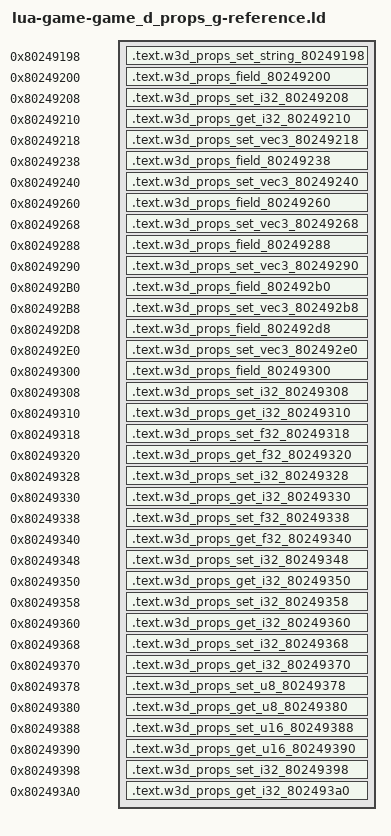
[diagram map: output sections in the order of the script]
/* Generated reference-only placements. All bodies are source-built. */
OUTPUT_FORMAT("elf32-powerpc")
OUTPUT_ARCH(powerpc)
ENTRY(w3d_props_set_string_80249198)
_SDA_BASE_ = 0x804b2540;
_SDA2_BASE_ = 0x804c2540;
w3d_string_release_header = 0x8020bb2c;
SECTIONS {
  .text.w3d_props_set_string_80249198 0x80249198 : { *(.text.w3d_props_set_string_80249198) }
  .text.w3d_props_field_80249200 0x80249200 : { *(.text.w3d_props_field_80249200) }
  .text.w3d_props_set_i32_80249208 0x80249208 : { *(.text.w3d_props_set_i32_80249208) }
  .text.w3d_props_get_i32_80249210 0x80249210 : { *(.text.w3d_props_get_i32_80249210) }
  .text.w3d_props_set_vec3_80249218 0x80249218 : { *(.text.w3d_props_set_vec3_80249218) }
  .text.w3d_props_field_80249238 0x80249238 : { *(.text.w3d_props_field_80249238) }
  .text.w3d_props_set_vec3_80249240 0x80249240 : { *(.text.w3d_props_set_vec3_80249240) }
  .text.w3d_props_field_80249260 0x80249260 : { *(.text.w3d_props_field_80249260) }
  .text.w3d_props_set_vec3_80249268 0x80249268 : { *(.text.w3d_props_set_vec3_80249268) }
  .text.w3d_props_field_80249288 0x80249288 : { *(.text.w3d_props_field_80249288) }
  .text.w3d_props_set_vec3_80249290 0x80249290 : { *(.text.w3d_props_set_vec3_80249290) }
  .text.w3d_props_field_802492b0 0x802492b0 : { *(.text.w3d_props_field_802492b0) }
  .text.w3d_props_set_vec3_802492b8 0x802492b8 : { *(.text.w3d_props_set_vec3_802492b8) }
  .text.w3d_props_field_802492d8 0x802492d8 : { *(.text.w3d_props_field_802492d8) }
  .text.w3d_props_set_vec3_802492e0 0x802492e0 : { *(.text.w3d_props_set_vec3_802492e0) }
  .text.w3d_props_field_80249300 0x80249300 : { *(.text.w3d_props_field_80249300) }
  .text.w3d_props_set_i32_80249308 0x80249308 : { *(.text.w3d_props_set_i32_80249308) }
  .text.w3d_props_get_i32_80249310 0x80249310 : { *(.text.w3d_props_get_i32_80249310) }
  .text.w3d_props_set_f32_80249318 0x80249318 : { *(.text.w3d_props_set_f32_80249318) }
  .text.w3d_props_get_f32_80249320 0x80249320 : { *(.text.w3d_props_get_f32_80249320) }
  .text.w3d_props_set_i32_80249328 0x80249328 : { *(.text.w3d_props_set_i32_80249328) }
  .text.w3d_props_get_i32_80249330 0x80249330 : { *(.text.w3d_props_get_i32_80249330) }
  .text.w3d_props_set_f32_80249338 0x80249338 : { *(.text.w3d_props_set_f32_80249338) }
  .text.w3d_props_get_f32_80249340 0x80249340 : { *(.text.w3d_props_get_f32_80249340) }
  .text.w3d_props_set_i32_80249348 0x80249348 : { *(.text.w3d_props_set_i32_80249348) }
  .text.w3d_props_get_i32_80249350 0x80249350 : { *(.text.w3d_props_get_i32_80249350) }
  .text.w3d_props_set_i32_80249358 0x80249358 : { *(.text.w3d_props_set_i32_80249358) }
  .text.w3d_props_get_i32_80249360 0x80249360 : { *(.text.w3d_props_get_i32_80249360) }
  .text.w3d_props_set_i32_80249368 0x80249368 : { *(.text.w3d_props_set_i32_80249368) }
  .text.w3d_props_get_i32_80249370 0x80249370 : { *(.text.w3d_props_get_i32_80249370) }
  .text.w3d_props_set_u8_80249378 0x80249378 : { *(.text.w3d_props_set_u8_80249378) }
  .text.w3d_props_get_u8_80249380 0x80249380 : { *(.text.w3d_props_get_u8_80249380) }
  .text.w3d_props_set_u16_80249388 0x80249388 : { *(.text.w3d_props_set_u16_80249388) }
  .text.w3d_props_get_u16_80249390 0x80249390 : { *(.text.w3d_props_get_u16_80249390) }
  .text.w3d_props_set_i32_80249398 0x80249398 : { *(.text.w3d_props_set_i32_80249398) }
  .text.w3d_props_get_i32_802493a0 0x802493a0 : { *(.text.w3d_props_get_i32_802493a0) }
  /DISCARD/ : { *(.text*) *(.rodata*) *(.data*) *(.bss*) *(.sdata*) *(.sbss*) *(.comment) }
}
